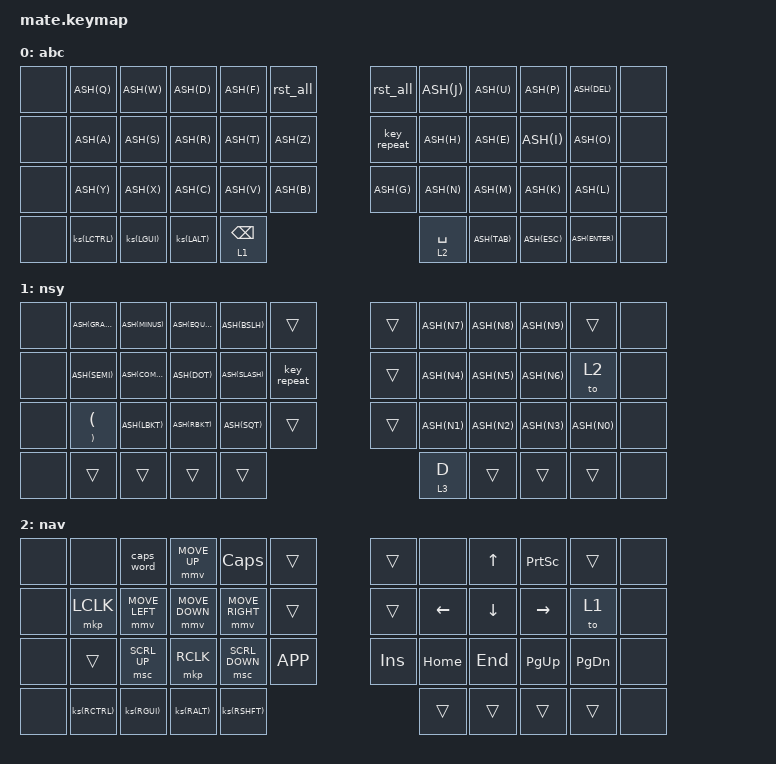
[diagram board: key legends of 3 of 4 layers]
#include <behaviors.dtsi>
#include <dt-bindings/zmk/keys.h>
#include <dt-bindings/zmk/bt.h>

&caps_word { continue-list = <MINUS UNDERSCORE BSPC DEL LEFT RIGHT DOT COMMA SEMI SLASH>; };
&sk { release-after-ms = <3000>; quick-release; ignore-modifiers; };
&sl { release-after-ms = <3000>; };

#define AZ  0
#define NS  1
#define NV  2
#define FU  3

#define xxxx &none
#define ____ &trans
#define ASH(l) &tkp LS(l) l 
#define ks(l) &ksk l l 
#define PARS &tkp RPAR LPAR

#define VX &tkp LC(X) LC(V)
#define CZ &tkp LC(Z) LC(C)
#define DELWRD LC(BSPC)
#define WRD_N RC(RIGHT)
#define WRD_P LC(LEFT)
#define TAB_N RA(RIGHT)
#define TAB_P LA(LEFT)


#define ZMK_MOUSE_DEFAULT_MOVE_VAL 1400  // 600
#define ZMK_MOUSE_DEFAULT_SCRL_VAL 30    // 10

#include <dt-bindings/zmk/mouse.h>
#include <behaviors/mouse_keys.dtsi>

&mmv {
  acceleration-exponent = <1>;      // 1
  time-to-max-speed-ms = <800>;    // 40
  delay-ms = <0>;                   // 0
};

&msc {
  acceleration-exponent = <1>;      // 0
  time-to-max-speed-ms = <40>;    // 500
  delay-ms = <0>;                   // 10
};

#define MOU_U &mmv MOVE_UP
#define MOU_D &mmv MOVE_DOWN
#define MOU_L &mmv MOVE_LEFT
#define MOU_R &mmv MOVE_RIGHT
#define SCR_U &msc SCRL_UP 
#define SCR_D &msc SCRL_DOWN
#define MCK_L &mkp LCLK 
#define MCK_R &mkp RCLK 



/ { 
    macros {
        rls_mods: rls_mods { compatible = "zmk,behavior-macro"; label = "ZM_rls_mods"; #binding-cells = <0>; wait-ms = <5>; tap-ms = <15>;
            bindings = <&macro_release &kp LSHFT &kp LCTRL &kp LALT &kp LGUI>; };
        rst_all:  rst_all  { compatible = "zmk,behavior-macro"; label = "ZM_rst_all"; #binding-cells = <0>; wait-ms = <5>; tap-ms = <15>;
            bindings = <&macro_release &kp LSHFT &kp LCTRL &kp LALT &kp LGUI>, <&macro_tap &to 0>; };
        dot_spc:  dot_spc  { compatible = "zmk,behavior-macro"; label = "ZM_dot_spc"; #binding-cells = <0>; wait-ms = <5>; tap-ms = <15>;
            bindings = <&macro_tap &kp DOT &kp SPACE &sk LSHFT>; };
    };

    behaviors {
        mk:  moml_kp      { compatible = "zmk,behavior-hold-tap"; label = "MOML_KP";      #binding-cells = <2>; flavor = "tap-preferred"; tapping-term-ms = <200>; bindings = <&mo>, <&kp>; }; 
        tkp: two_kp       { compatible = "zmk,behavior-hold-tap"; label = "TWO_KP";       #binding-cells = <2>; flavor = "tap-preferred"; tapping-term-ms = <175>; bindings = <&kp>, <&kp>; }; 
        ksk: kp_sk        { compatible = "zmk,behavior-hold-tap"; label = "KP_SK";        #binding-cells = <2>; flavor = "tap-preferred"; tapping-term-ms = <175>; bindings = <&kp>, <&sk>; }; 
        mmd: moml_macro   { compatible = "zmk,behavior-hold-tap"; label = "MOML_MACRO";   #binding-cells = <2>; flavor = "tap-preferred"; tapping-term-ms = <200>; bindings = <&mo>, <&dot_spc>; }; 
    };
  
    keymap {
        compatible = "zmk,keymap";
        abc {
            bindings = <
                xxxx ASH(Q)  ASH(W)  ASH(D)  ASH(F)  &rst_all        &rst_all     ASH(J)  ASH(U)  ASH(P)  ASH(DEL)   xxxx
                xxxx ASH(A)  ASH(S)  ASH(R)  ASH(T)  ASH(Z)          &key_repeat  ASH(H)  ASH(E)  ASH(I)  ASH(O)     xxxx
                xxxx ASH(Y)  ASH(X)  ASH(C)  ASH(V)  ASH(B)          ASH(G)       ASH(N)  ASH(M)  ASH(K)  ASH(L)     xxxx
                xxxx ks(LCTRL) ks(LGUI) ks(LALT)  &mk 1 BSPC             &mk 2 SPACE  ASH(TAB)  ASH(ESC)  ASH(ENTER) xxxx
            >;  
        };

        nsy {
            bindings = <
                xxxx ASH(GRAVE)  ASH(MINUS)  ASH(EQUAL) ASH(BSLH)  ____         ____  ASH(N7)  ASH(N8)  ASH(N9)  ____     xxxx
                xxxx ASH(SEMI)   ASH(COMMA)  ASH(DOT)   ASH(SLASH) &key_repeat  ____  ASH(N4)  ASH(N5)  ASH(N6)  &to 2    xxxx
                xxxx PARS        ASH(LBKT)   ASH(RBKT)  ASH(SQT)   ____         ____  ASH(N1)  ASH(N2)  ASH(N3)  ASH(N0)  xxxx
                xxxx ____  ____  ____  ____                                                   &mmd 3 D  ____  ____  ____  xxxx
            >;
        };

        nav { 
            bindings = <
                xxxx xxxx  &caps_word  MOU_U  &kp CAPS  ____      ____     xxxx      &kp UP    &kp PSCRN  ____       xxxx
                xxxx MCK_L  MOU_L      MOU_D  MOU_R     ____      ____     &kp LEFT  &kp DOWN  &kp RIGHT  &to 1      xxxx
                xxxx ____   SCR_U      MCK_R  SCR_D  &kp K_APP    &kp INS  &kp HOME  &kp END   &kp PG_UP  &kp PG_DN  xxxx
                xxxx ks(RCTRL) ks(RGUI) ks(RALT)  ks(RSHFT)                                             ____  ____  ____  ____  xxxx
            >;
        };

        fun {
            bindings = <
                xxxx xxxx  &kp C_MUTE  &kp C_VOL_DN  &kp C_VOL_UP  xxxx     xxxx  xxxx  &kp C_BRI_DN  &kp C_BRI_UP  xxxx  xxxx 
                xxxx &kp F1  &kp F2  &kp F3  &kp F4  &kp F5                      &kp F6  &kp F7  &kp F8  &kp F9  &kp F10  xxxx
                xxxx &kt LSHFT  &kt LCTRL  &kt LGUI  &kt LALT                    xxxx    xxxx    xxxx   &kp F11  &kp F12  xxxx
                xxxx ____  ____  ____  ks(LSHFT)                                                  ____  ____  ____  ____  xxxx
            >;
        };
    };
};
